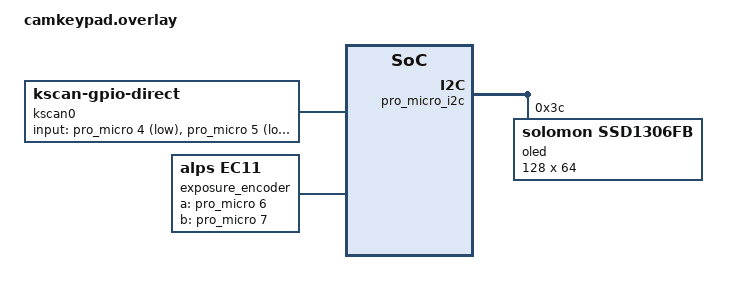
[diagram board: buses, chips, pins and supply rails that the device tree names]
/ {
    chosen {
        zephyr,display = &oled;
        zmk,kscan = &kscan0;
    };

    // One switch per pin, to GND. Positions in order: D4, D5, D8 (encoder click), D9, D14, D15.
    kscan0: kscan {
        compatible = "zmk,kscan-gpio-direct";
        wakeup-source;

        input-gpios
            = <&pro_micro 4 (GPIO_ACTIVE_LOW | GPIO_PULL_UP)>
            , <&pro_micro 5 (GPIO_ACTIVE_LOW | GPIO_PULL_UP)>
            , <&pro_micro 8 (GPIO_ACTIVE_LOW | GPIO_PULL_UP)>
            , <&pro_micro 9 (GPIO_ACTIVE_LOW | GPIO_PULL_UP)>
            , <&pro_micro 14 (GPIO_ACTIVE_LOW | GPIO_PULL_UP)>
            , <&pro_micro 15 (GPIO_ACTIVE_LOW | GPIO_PULL_UP)>
            ;
    };

    // Common pin to GND.
    exposure_encoder: exposure_encoder {
        compatible = "alps,ec11";
        a-gpios = <&pro_micro 6 (GPIO_ACTIVE_HIGH | GPIO_PULL_UP)>;
        b-gpios = <&pro_micro 7 (GPIO_ACTIVE_HIGH | GPIO_PULL_UP)>;
        steps = <80>;
        status = "okay";
    };

    sensors: sensors {
        compatible = "zmk,keymap-sensors";
        sensors = <&exposure_encoder>;
        triggers-per-rotation = <20>;
    };
};

// SSD1306 128x64 on D2 (SDA) / D3 (SCL). segment-remap and com-invdir rotate the image
// 180 degrees to suit how the panel is mounted.
&pro_micro_i2c {
    status = "okay";

    oled: ssd1306@3c {
        compatible = "solomon,ssd1306fb";
        reg = <0x3c>;
        width = <128>;
        height = <64>;
        segment-offset = <0>;
        page-offset = <0>;
        display-offset = <0>;
        multiplex-ratio = <63>;
        prechargep = <0x22>;
        segment-remap;
        com-invdir;
        inversion-on;
    };
};
